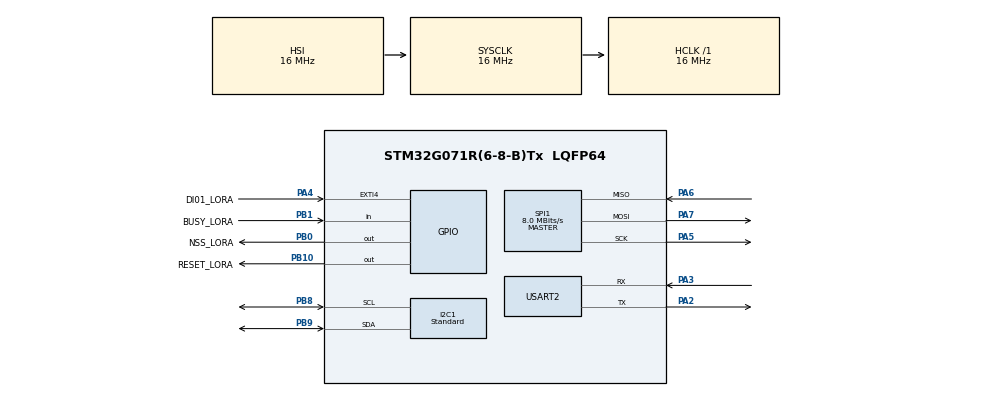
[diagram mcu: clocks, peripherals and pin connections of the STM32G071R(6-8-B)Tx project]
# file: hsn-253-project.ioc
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I2C1.CustomTiming=Enabled
I2C1.I2C_Speed_Mode=I2C_Standard
I2C1.Timing=0x00503D58
Mcu.Family=STM32G0
Mcu.Name=STM32G071R(6-8-B)Tx
Mcu.Package=LQFP64
PA2.Mode=Asynchronous
PA2.Signal=USART2_TX
PA3.Mode=Asynchronous
PA3.Signal=USART2_RX
PA4.GPIO_Label=DI01_LORA
PA4.Signal=GPXTI4
PA5.Mode=Full_Duplex_Master
PA5.Signal=SPI1_SCK
PA6.Mode=Full_Duplex_Master
PA6.Signal=SPI1_MISO
PA7.Mode=Full_Duplex_Master
PA7.Signal=SPI1_MOSI
PB0.GPIO_Label=NSS_LORA
PB0.Signal=GPIO_Output
PB1.GPIO_Label=BUSY_LORA
PB1.Signal=GPIO_Input
PB10.GPIO_Label=RESET_LORA
PB10.Signal=GPIO_Output
PB8.Mode=I2C
PB8.Signal=I2C1_SCL
PB9.Mode=I2C
PB9.Signal=I2C1_SDA
ProjectManager.HeapSize=0x200
ProjectManager.StackSize=0x400
ProjectManager.TargetToolchain=STM32CubeIDE
RCC.AHBFreq_Value=16000000
RCC.CortexFreq_Value=16000000
RCC.EXTERNAL_CLOCK_VALUE=12288000
RCC.HCLKFreq_Value=16000000
RCC.HSE_VALUE=8000000
RCC.HSI_VALUE=16000000
RCC.LSE_VALUE=32768
RCC.SYSCLKFreq_VALUE=16000000
RCC.VCOOutputFreq_Value=128000000
SPI1.CalculateBaudRate=8.0 MBits/s
SPI1.DataSize=SPI_DATASIZE_8BIT
SPI1.Direction=SPI_DIRECTION_2LINES
SPI1.Mode=SPI_MODE_MASTER
SPI1.VirtualType=VM_MASTER
USART2.VirtualMode-Asynchronous=VM_ASYNC
board=NUCLEO-G071RB
PB0.GPIO_Output=NSS_LORA
PB1.GPIO_Output=RESET_LORA
PB2.GPIO_Input=BUSY_LORA
PA4.GPIO_EXTI=DI01_LORA
NVIC_EXTI4_IRQn=true

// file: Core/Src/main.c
/* USER CODE BEGIN Header */
/**
  ******************************************************************************
  * @file           : main.c
  * @brief          : Main program body
  ******************************************************************************
  * @attention
  *
  * Copyright (c) 2025 STMicroelectronics.
  * All rights reserved.
  *
  ******************************************************************************
  */
/* USER CODE END Header */
#include "main.h"

/* USER CODE BEGIN Includes */
#include "SX1262.h"
#include "bme68x.h"
#include <stdbool.h>
#include <string.h>
#include <stdio.h>
#include "stm32g0xx_hal.h"
/* USER CODE END Includes */

/* USER CODE BEGIN PD */

// SX1262 LoRa HAT Pin definitions (updated as per your wiring!)
#define LORA_NSS_PORT        GPIOB
#define LORA_NSS_PIN         GPIO_PIN_0
#define LORA_RST_PORT        GPIOB
#define LORA_RST_PIN         GPIO_PIN_1
#define LORA_BUSY_PORT       GPIOB
#define LORA_BUSY_PIN        GPIO_PIN_2
#define LORA_DIO1_PORT       GPIOA
#define LORA_DIO1_PIN        GPIO_PIN_4

/* USER CODE END PD */

I2C_HandleTypeDef hi2c1;

SPI_HandleTypeDef hspi1;

UART_HandleTypeDef huart2;

/* USER CODE BEGIN PV */
#define BME68X_I2C_ADDR 0x77
struct bme68x_dev gas_sensor;
struct bme68x_conf conf;
struct bme68x_heatr_conf heatr_conf;
struct bme68x_data data[3];
uint8_t n_fields = 0;
int8_t rslt;

static int8_t user_i2c_read(uint8_t reg_addr, uint8_t *data, uint32_t len, void *intf_ptr);
static int8_t user_i2c_write(uint8_t reg_addr, const uint8_t *data, uint32_t len, void *intf_ptr);
static void user_delay_us(uint32_t period, void *intf_ptr);
/* USER CODE END PV */

void SystemClock_Config(void);
static void MX_GPIO_Init(void);
static void MX_USART2_UART_Init(void);
static void MX_I2C1_Init(void);
static void MX_SPI1_Init(void);

/* USER CODE BEGIN 0 */

static void user_delay_us(uint32_t period, void *intf_ptr)
{
    uint32_t start = HAL_GetTick();
    while ((HAL_GetTick() - start) * 1000 < period);
}

static int8_t user_i2c_read(uint8_t reg_addr, uint8_t *data, uint32_t len, void *intf_ptr)
{
    I2C_HandleTypeDef *hi2c = (I2C_HandleTypeDef *)intf_ptr;
    if (HAL_I2C_Mem_Read(hi2c, BME68X_I2C_ADDR << 1, reg_addr, I2C_MEMADD_SIZE_8BIT, data, len, HAL_MAX_DELAY) != HAL_OK) {
        char err[] = "I2C read failed\r\n";
        HAL_UART_Transmit(&huart2, (uint8_t*)err, strlen(err), HAL_MAX_DELAY);
        return -1;
    }
    return 0;
}

static int8_t user_i2c_write(uint8_t reg_addr, const uint8_t *data, uint32_t len, void *intf_ptr)
{
    I2C_HandleTypeDef *hi2c = (I2C_HandleTypeDef *)intf_ptr;
    if (HAL_I2C_Mem_Write(hi2c, BME68X_I2C_ADDR << 1, reg_addr, I2C_MEMADD_SIZE_8BIT, (uint8_t*)data, len, HAL_MAX_DELAY) != HAL_OK)
        return -1;
    return 0;
}

void log_debug(const char *msg) {
    bool isDebug = true;
    char buffer[200];
    if(isDebug)
    {
        snprintf(buffer, sizeof(buffer), "[DEBUG] %s\r\n", msg);
        HAL_UART_Transmit(&huart2, (uint8_t *)buffer, strlen(buffer), HAL_MAX_DELAY);
    }
}

void log_info(const char *msg) {
    char buffer[200];
    snprintf(buffer, sizeof(buffer), "%s\r\n", msg);
    HAL_UART_Transmit(&huart2, (uint8_t *)buffer, strlen(buffer), HAL_MAX_DELAY);
}

// --- SX1262 TX Done Callback via DIO1 Interrupt ---
void HAL_GPIO_EXTI_Callback(uint16_t GPIO_Pin)
{
    if(GPIO_Pin == LORA_DIO1_PIN) {
        log_debug("SX1262 TX complete (DIO1 interrupt detected)");
        // You can set a flag here for your application logic if needed
    }
}
/* USER CODE END 0 */

int main(void)
{

  /* USER CODE BEGIN 1 */
  log_debug("System Initialization Started");
  /* USER CODE END 1 */

  /* MCU Configuration--------------------------------------------------------*/

  /* Reset of all peripherals, Initializes the Flash interface and the Systick. */
  HAL_Init();

  /* Configure the system clock */
  SystemClock_Config();

  /* Initialize all configured peripherals */
  MX_GPIO_Init();
  MX_USART2_UART_Init();
  MX_I2C1_Init();
  MX_SPI1_Init();
  /* USER CODE BEGIN 2 */

  // --- SX1262 LoRa HAT Initialization ---
  SX1262_Get_st()->Busy_Pin  = LORA_BUSY_PIN;
  SX1262_Get_st()->Busy_Port = LORA_BUSY_PORT;
  SX1262_Get_st()->NSS_Pin   = LORA_NSS_PIN;
  SX1262_Get_st()->NSS_Port  = LORA_NSS_PORT;
  SX1262_Get_st()->Reset_Pin = LORA_RST_PIN;
  SX1262_Get_st()->Reset_Port= LORA_RST_PORT;
  SX1262_Get_st()->SPI = hspi1;

  log_debug("Initializing SX1262...");
  SX1262_Init();

  uint8_t status = SX1262_getstatus();
  char msg[64];
  snprintf(msg, sizeof(msg), "SX1262 status: 0x%02X\r\n", status);
  log_debug(msg);

  log_debug("Initializing BME68x...");

  // Set up BME68x sensor interface
  gas_sensor.intf = BME68X_I2C_INTF;
  gas_sensor.read = user_i2c_read;
  gas_sensor.write = user_i2c_write;
  gas_sensor.delay_us = user_delay_us;
  gas_sensor.intf_ptr = &hi2c1;

  rslt = bme68x_init(&gas_sensor);
  if (rslt != BME68X_OK) {
      log_debug("Sensor initialization failed. Halting.");
      while (1);
  }

  uint8_t chip_id = 0;
  rslt = bme68x_get_regs(BME68X_REG_CHIP_ID, &chip_id, 1, &gas_sensor);
  if (rslt == BME68X_OK) {
      char id_msg[64];
      snprintf(id_msg, sizeof(id_msg), "BME68x Chip ID: 0x%02X (Expected: 0x%02X)", chip_id, BME68X_CHIP_ID);
      log_debug(id_msg);
  } else {
      log_debug("Failed to read Chip ID");
  }

  log_debug("Configuring BME68x sensor...");

  // Oversampling and filter config
  conf.os_hum = BME68X_OS_2X;
  conf.os_temp = BME68X_OS_8X;
  conf.os_pres = BME68X_OS_4X;
  conf.filter = BME68X_FILTER_SIZE_3;

  if (bme68x_set_conf(&conf, &gas_sensor) != BME68X_OK)
      log_debug("Failed to apply sensor config");

  // Heater configuration
  heatr_conf.enable = BME68X_ENABLE;
  heatr_conf.heatr_temp = 300;
  heatr_conf.heatr_dur = 100;

  if (bme68x_set_heatr_conf(BME68X_FORCED_MODE, &heatr_conf, &gas_sensor) != BME68X_OK)
      log_debug("Failed to apply heater config");

  log_debug("BME68x configuration complete.");

  const char *intro_msg =
      "\r\n=== BME68x Sensor + LoRa Terminal ===\r\n"
      "Sensor Data:\r\n"
      "  <duration> <mode>\r\n"
      "Where:\r\n"
      "  duration - Number of seconds to print (e.g., 5)\r\n"
      "  mode     - One of the following:\r\n"
      "             temp  - Show Temperature in Celsius\r\n"
      "             humi  - Show Humidity in %%\r\n"
      "             press - Show Pressure in hPa\r\n"
      "Examples:\r\n"
      "  10 temp   - Show temperature every second for 10 seconds\r\n"
      "  5 humi    - Show humidity for 5 seconds\r\n"
      "\r\nLoRa Communication:\r\n"
      "  lora <message>   - Transmit message over LoRa\r\n"
      "  Example: lora Hello World\r\n"
      "\r\nArithmetic Operations:\r\n"
      "  add a b [c ...]  - Add numbers\r\n"
      "  sub a b [c ...]  - Subtract numbers\r\n"
      "  mul a b [c ...]  - Multiply numbers\r\n"
      "  div a b [c ...]  - Divide numbers (left to right)\r\n"
      "  Example: add 2 3 4\r\n"
      "\r\nType 'help' to show this message again.\r\n"
      "===========================================\r\n";

  /* USER CODE END 2 */

  /* Infinite loop */
  /* USER CODE BEGIN WHILE */
  while (1)
  {
      char rx_buffer[32] = {0};
      uint8_t idx = 0;
      char ch;

      while (1) {
          HAL_UART_Receive(&huart2, (uint8_t *)&ch, 1, HAL_MAX_DELAY);
          HAL_UART_Transmit(&huart2, (uint8_t *)&ch, 1, HAL_MAX_DELAY); // echo

          if (ch == '\r' || ch == '\n') {
              rx_buffer[idx] = '\0';
              break;
          } else if (idx < sizeof(rx_buffer) - 1) {
              rx_buffer[idx++] = ch;
          }
      }

      // Skip if empty input
      if (strlen(rx_buffer) == 0) {
          continue;
      }

      int duration = 0;
      char mode[16] = {0};

      if (strcmp(rx_buffer, "help") == 0 || strcmp(rx_buffer, "start") == 0) {
          HAL_UART_Transmit(&huart2, (uint8_t *)intro_msg, strlen(intro_msg), HAL_MAX_DELAY);
          continue;
      }

      char copy[64];
      strncpy(copy, rx_buffer, sizeof(copy) - 1);
      copy[sizeof(copy) - 1] = '\0'; // Ensure null termination

      char *cmd = strtok(copy, " ");
      if (!cmd) continue;

      if (strcmp(cmd, "lora") == 0) {
          char *message = strtok(NULL, "");
          if (message && strlen(message) > 0) {
              char info[128];
              snprintf(info, sizeof(info),
                  "\r\n=== LoRa Transmission ===\r\n"
                  "Transmitting: \"%s\"\r\n"
                  "==========================\r\n", message);
              HAL_UART_Transmit(&huart2, (uint8_t *)info, strlen(info), HAL_MAX_DELAY);

              SX1262_Transmit((uint8_t *)message, strlen(message));
              HAL_UART_Transmit(&huart2, (uint8_t *)"LoRa TX complete.\r\n", 19, HAL_MAX_DELAY);
          } else {
              HAL_UART_Transmit(&huart2, (uint8_t *)"Usage: lora <message>\r\n", 24, HAL_MAX_DELAY);
          }
          continue;
      }

      if (strcmp(cmd, "add") == 0 || strcmp(cmd, "sub") == 0 || strcmp(cmd, "mul") == 0 || strcmp(cmd, "div") == 0) {
          int result = 0, value;
          bool first = true;
          char *arg;
          while ((arg = strtok(NULL, " ")) != NULL) {
              if (sscanf(arg, "%d", &value) != 1) {
                  HAL_UART_Transmit(&huart2, (uint8_t *)"Invalid number\r\n", 17, HAL_MAX_DELAY);
                  break;
              }

              if (first) {
                  result = value;
                  first = false;
                  continue;
              }

              if (strcmp(cmd, "add") == 0) result += value;
              else if (strcmp(cmd, "sub") == 0) result -= value;
              else if (strcmp(cmd, "mul") == 0) result *= value;
              else if (strcmp(cmd, "div") == 0) {
                  if (value == 0) {
                      HAL_UART_Transmit(&huart2, (uint8_t *)"Divide by 0\r\n", 14, HAL_MAX_DELAY);
                      break;
                  }
                  result /= value;
              }
          }

          char result_msg[64];
          snprintf(result_msg, sizeof(result_msg), "Result: %d\r\n", result);
          HAL_UART_Transmit(&huart2, (uint8_t *)result_msg, strlen(result_msg), HAL_MAX_DELAY);
          continue;
      }

      if (sscanf(rx_buffer, "%d %15s", &duration, mode) != 2) {
          const char *msg = "Invalid format. Use: <duration> <mode>\r\n";
          HAL_UART_Transmit(&huart2, (uint8_t *)msg, strlen(msg), HAL_MAX_DELAY);
          continue;
      }

      char echo[64];
      snprintf(echo, sizeof(echo), "\r\n> Duration: %d sec | Mode: %s\r\n", duration, mode);
      HAL_UART_Transmit(&huart2, (uint8_t *)echo, strlen(echo), HAL_MAX_DELAY);

      bool dataReceived = false;
      for (int t = 0; t < duration; t++) {
          rslt = bme68x_set_op_mode(BME68X_FORCED_MODE, &gas_sensor);
          if (rslt != BME68X_OK) {
              HAL_UART_Transmit(&huart2, (uint8_t *)"Set op mode failed\r\n", 21, HAL_MAX_DELAY);
              break;
          }

          uint32_t meas_dur = bme68x_get_meas_dur(BME68X_FORCED_MODE, &conf, &gas_sensor);
          gas_sensor.delay_us(meas_dur + 10000, gas_sensor.intf_ptr);

          rslt = bme68x_get_data(BME68X_FORCED_MODE, data, &n_fields, &gas_sensor);

          if (rslt == BME68X_OK && n_fields > 0) {
              for (uint8_t i = 0; i < n_fields; i++) {
                  dataReceived = true;
                  char msg[64];
                  if (strcmp(mode, "temp") == 0) {
                      snprintf(msg, sizeof(msg), "Temperature: %.2f °C\r\n", data[i].temperature);
                  } else if (strcmp(mode, "humi") == 0) {
                      snprintf(msg, sizeof(msg), "Humidity: %.2f %%\r\n", data[i].humidity);
                  } else if (strcmp(mode, "press") == 0) {
                      snprintf(msg, sizeof(msg), "Pressure: %.2f hPa\r\n", data[i].pressure);
                  } else {
                        char err[64];
                        snprintf(err, sizeof(err), "Unknown mode: %s\r\n", mode);
                        HAL_UART_Transmit(&huart2, (uint8_t *)err, strlen(err), HAL_MAX_DELAY);
                        t = duration;
                  }
                  // Transmit over UART (debug/log)
                  HAL_UART_Transmit(&huart2, (uint8_t *)msg, strlen(msg), HAL_MAX_DELAY);

                  // Transmit over LoRa
//                  SX1262_Transmit((uint8_t *)msg, strlen(msg));
              }
          } else if(dataReceived) {
              HAL_UART_Transmit(&huart2, (uint8_t *)"Sensor read error\r\n", 20, HAL_MAX_DELAY);
          }

          HAL_Delay(1000); // wait 1 second
      }
  }
    /* USER CODE END WHILE */

}

void SystemClock_Config(void)
{
  RCC_OscInitTypeDef RCC_OscInitStruct = {0};
  RCC_ClkInitTypeDef RCC_ClkInitStruct = {0};

  /** Configure the main internal regulator output voltage
  */
  HAL_PWREx_ControlVoltageScaling(PWR_REGULATOR_VOLTAGE_SCALE1);

  /** Initializes the RCC Oscillators according to the specified parameters
  * in the RCC_OscInitTypeDef structure.
  */
  RCC_OscInitStruct.OscillatorType = RCC_OSCILLATORTYPE_HSI;
  RCC_OscInitStruct.HSIState = RCC_HSI_ON;
  RCC_OscInitStruct.HSIDiv = RCC_HSI_DIV1;
  RCC_OscInitStruct.HSICalibrationValue = RCC_HSICALIBRATION_DEFAULT;
  RCC_OscInitStruct.PLL.PLLState = RCC_PLL_NONE;
  if (HAL_RCC_OscConfig(&RCC_OscInitStruct) != HAL_OK)
  {
    Error_Handler();
  }

  /** Initializes the CPU, AHB and APB buses clocks
  */
  RCC_ClkInitStruct.ClockType = RCC_CLOCKTYPE_HCLK|RCC_CLOCKTYPE_SYSCLK
                              |RCC_CLOCKTYPE_PCLK1;
  RCC_ClkInitStruct.SYSCLKSource = RCC_SYSCLKSOURCE_HSI;
  RCC_ClkInitStruct.AHBCLKDivider = RCC_SYSCLK_DIV1;
  RCC_ClkInitStruct.APB1CLKDivider = RCC_HCLK_DIV1;

  if (HAL_RCC_ClockConfig(&RCC_ClkInitStruct, FLASH_LATENCY_0) != HAL_OK)
  {
    Error_Handler();
  }
}

static void MX_I2C1_Init(void)
{

  hi2c1.Instance = I2C1;
  hi2c1.Init.Timing = 0x00503D58;
  hi2c1.Init.OwnAddress1 = 0;
  hi2c1.Init.AddressingMode = I2C_ADDRESSINGMODE_7BIT;
  hi2c1.Init.DualAddressMode = I2C_DUALADDRESS_DISABLE;
  hi2c1.Init.OwnAddress2 = 0;
  hi2c1.Init.OwnAddress2Masks = I2C_OA2_NOMASK;
  hi2c1.Init.GeneralCallMode = I2C_GENERALCALL_DISABLE;
  hi2c1.Init.NoStretchMode = I2C_NOSTRETCH_DISABLE;
  if (HAL_I2C_Init(&hi2c1) != HAL_OK)
  {
    Error_Handler();
  }

  /** Configure Analogue filter
  */
  if (HAL_I2CEx_ConfigAnalogFilter(&hi2c1, I2C_ANALOGFILTER_ENABLE) != HAL_OK)
  {
    Error_Handler();
  }

  /** Configure Digital filter
  */
  if (HAL_I2CEx_ConfigDigitalFilter(&hi2c1, 0) != HAL_OK)
  {
    Error_Handler();
  }

}

static void MX_SPI1_Init(void)
{

  /* SPI1 parameter configuration*/
  hspi1.Instance = SPI1;
  hspi1.Init.Mode = SPI_MODE_MASTER;
  hspi1.Init.Direction = SPI_DIRECTION_2LINES;
  hspi1.Init.DataSize = SPI_DATASIZE_8BIT;
  hspi1.Init.CLKPolarity = SPI_POLARITY_LOW;
  hspi1.Init.CLKPhase = SPI_PHASE_1EDGE;
  hspi1.Init.NSS = SPI_NSS_SOFT;
  hspi1.Init.BaudRatePrescaler = SPI_BAUDRATEPRESCALER_2;
  hspi1.Init.FirstBit = SPI_FIRSTBIT_MSB;
  hspi1.Init.TIMode = SPI_TIMODE_DISABLE;
  hspi1.Init.CRCCalculation = SPI_CRCCALCULATION_DISABLE;
  hspi1.Init.CRCPolynomial = 7;
  hspi1.Init.CRCLength = SPI_CRC_LENGTH_DATASIZE;
  hspi1.Init.NSSPMode = SPI_NSS_PULSE_ENABLE;
  if (HAL_SPI_Init(&hspi1) != HAL_OK)
  {
    Error_Handler();
  }

}

static void MX_USART2_UART_Init(void)
{

  huart2.Instance = USART2;
  huart2.Init.BaudRate = 115200;
  huart2.Init.WordLength = UART_WORDLENGTH_8B;
  huart2.Init.StopBits = UART_STOPBITS_1;
  huart2.Init.Parity = UART_PARITY_NONE;
  huart2.Init.Mode = UART_MODE_TX_RX;
  huart2.Init.HwFlowCtl = UART_HWCONTROL_NONE;
  huart2.Init.OverSampling = UART_OVERSAMPLING_16;
  huart2.Init.OneBitSampling = UART_ONE_BIT_SAMPLE_DISABLE;
  huart2.Init.ClockPrescaler = UART_PRESCALER_DIV1;
  huart2.AdvancedInit.AdvFeatureInit = UART_ADVFEATURE_NO_INIT;
  if (HAL_UART_Init(&huart2) != HAL_OK)
  {
    Error_Handler();
  }
  if (HAL_UARTEx_SetTxFifoThreshold(&huart2, UART_TXFIFO_THRESHOLD_1_8) != HAL_OK)
  {
    Error_Handler();
  }
  if (HAL_UARTEx_SetRxFifoThreshold(&huart2, UART_RXFIFO_THRESHOLD_1_8) != HAL_OK)
  {
    Error_Handler();
  }
  if (HAL_UARTEx_DisableFifoMode(&huart2) != HAL_OK)
  {
    Error_Handler();
  }

}

static void MX_GPIO_Init(void)
{
  GPIO_InitTypeDef GPIO_InitStruct = {0};

  /* GPIO Ports Clock Enable */
  __HAL_RCC_GPIOA_CLK_ENABLE();
  __HAL_RCC_GPIOB_CLK_ENABLE();

  /*Configure GPIO pin Output Level */
  HAL_GPIO_WritePin(GPIOB, GPIO_PIN_0|GPIO_PIN_1|GPIO_PIN_2, GPIO_PIN_RESET);

  // Configure DIO1_LORA (PA4) as EXTI (Interrupt) Input
  GPIO_InitStruct.Pin = GPIO_PIN_4;
  GPIO_InitStruct.Mode = GPIO_MODE_IT_RISING;
  GPIO_InitStruct.Pull = GPIO_NOPULL;
  HAL_GPIO_Init(GPIOA, &GPIO_InitStruct);

  // Configure NSS_LORA (PB0), RESET (PB1), BUSY (PB2) as output
  GPIO_InitStruct.Pin = GPIO_PIN_0|GPIO_PIN_1|GPIO_PIN_2;
  GPIO_InitStruct.Mode = GPIO_MODE_OUTPUT_PP;
  GPIO_InitStruct.Pull = GPIO_NOPULL;
  GPIO_InitStruct.Speed = GPIO_SPEED_FREQ_LOW;
  HAL_GPIO_Init(GPIOB, &GPIO_InitStruct);

}

void Error_Handler(void)
{
  __disable_irq();
  while (1)
  {
  }
}
